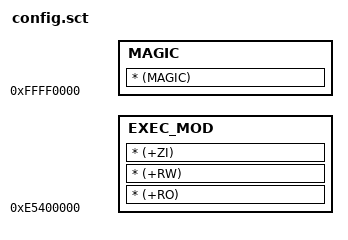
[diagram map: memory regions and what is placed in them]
;/*
;*********************************************************************************************************
;*                                                    MELIS
;*                                    the Easy Portable/Player Develop Kits
;*                                               makefile Module
;*
;*                                  (c) Copyright 2010-2014, Calder.Chen China
;*                                             All Rights Reserved
;*
;* File    : config.sct
;* By      : CC
;* Version : v1.0
;* Date    : 2011-01-01 08:30
;* Descript:
;* Update  :    date            auther          ver         notes
;*           2011-01-01           CC            1.0     create this file.
;*********************************************************************************************************
;*/

LO_FIRST 0xe5400000 0x10000
{
    EXEC_MOD  0xe5400000                           ;// 内核代码和数据区,其中30是用于存放KRNL_HEAD代码
    {
        * (+RO)
        * (+RW)
        * (+ZI)
	}
    MAGIC  0xFFFF0000
    {
        * (MAGIC)
    }
}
